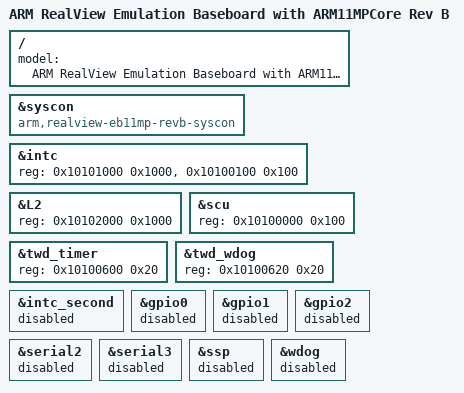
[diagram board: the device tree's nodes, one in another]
#include "arm-realview-eb-11mp.dts"
/ {
	model = "ARM RealView Emulation Baseboard with ARM11MPCore Rev B";
};
&syscon {
	compatible = "arm,realview-eb11mp-revb-syscon", "arm,realview-eb-syscon", "syscon", "simple-mfd";
};
&intc {
	reg = <0x10101000 0x1000>,
	      <0x10100100 0x100>;
};
&L2 {
	reg = <0x10102000 0x1000>;
};
&scu {
	reg = <0x10100000 0x100>;
};
&twd_timer {
	reg = <0x10100600 0x20>;
};
&twd_wdog {
	reg = <0x10100620 0x20>;
};
&intc_second {
	status = "disabled";
};
&gpio0 {
	status = "disabled";
};
&gpio1 {
	status = "disabled";
};
&gpio2 {
	status = "disabled";
};
&serial2 {
	status = "disabled";
};
&serial3 {
	status = "disabled";
};
&ssp {
	status = "disabled";
};
&wdog {
	status = "disabled";
};
